# dm646x_cslr_pci_003 register map
Vendor: Texas Instruments
Peripheral module from a debugger description file.
Registers are 32-bit, access not given, reset 0x0 unless marked. A register's access mark holds for its fields unless they carry their own. Offsets are as the file gives them; lines under a group give offsets from that group; [hi:lo] are bit positions; {n}, {i} and the like mark numbered series; 'fields as' and 'values as' point back to an identical list; <NAME> marks a mode.

## PCI — The PCI module allows communication with devices complaint to the PCI Local Bus Specification (revision 2.3) via a 32-bit address/data bus operating at speeds up to 33 MHz.
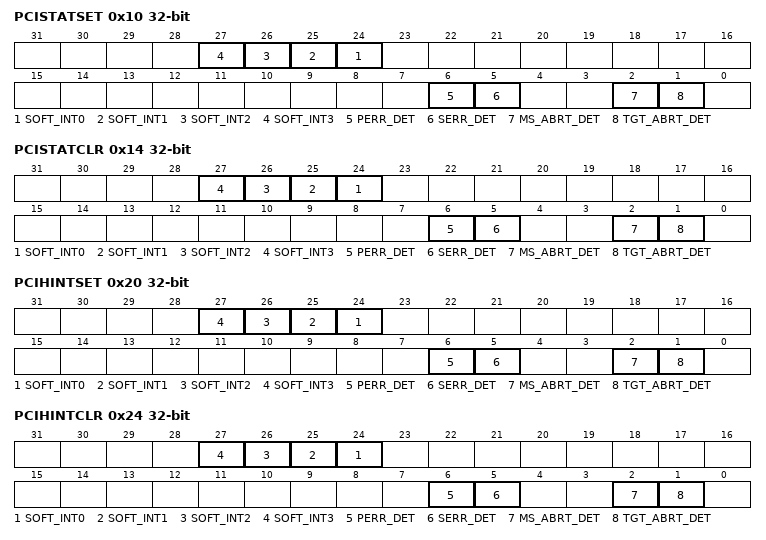
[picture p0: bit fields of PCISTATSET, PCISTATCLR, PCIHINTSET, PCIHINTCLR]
0x10 PCISTATSET — Used to set bits in the internal status register and to read the status of the internal status register.
  [all] fields
    0=NOTSET (Status bit is not set.); 1=SET (Status bit is set.)
  [n+24] SOFT_INT{n} rw (n=0..3) — Software interrupt status bit. Reading these bits returns the value of the SOFT_INT{n} bit in the internal status register. Writing a 1 to these bits sets the SOFT_INT{n} bit in the internal status register. Writing a 0 has no effect.
  [6] PERR_DET rw — Parity error detect status bit. Reading this bit returns the value of the PERR_DET bit in the internal status register. Writing 1 to this bit sets the PERR_DET bit in the internal status register.
  [5] SERR_DET rw — System error detect status bit. Reading this bit returns the value of the SERR_DET bit in the internal status register. Writing 1 to this bit sets the SERR_DET bit in the internal status register.
  [2] MS_ABRT_DET rw — Master abort detect status bit. Reading this bit returns the value of the MS_ABRT_DET bit in the internal status register. Writing 1 to this bit sets the MS_ABRT_DET bit in the internal status register.
  [1] TGT_ABRT_DET rw — Target abort detect status bit. Reading this bit returns the value of the TGT_ABRT_DET bit in the internal status register. Writing 1 to this bit sets the TGT_ABRT_DET bit in the internal status register.
0x14 PCISTATCLR — Used to clear bits in the internal status register and to read the status of the internal status register.
  [all] fields
    values as the fields of PCISTATSET
  [n+24] SOFT_INT{n} rw (n=0..3) — Software interrupt status bit. Reading these bits returns the value of the SOFT_INT{n} bit in the internal status register. Writing a 1 to these bits clears the SOFT_INT{n} bit in the internal status register. Writing a 0 has no effect.
  [6] PERR_DET rw — Parity error detect status bit. Reading this bit returns the value of the PERR_DET bit in the internal status register. Writing 1 to this bit clears the PERR_DET bit in the internal status register.
  [5] SERR_DET rw — System error detect status bit. Reading this bit returns the value of the SERR_DET bit in the internal status register. Writing 1 to this bit clears the SERR_DET bit in the internal status register.
  [2] MS_ABRT_DET rw — Master abort detect status bit. Reading this bit returns the value of the MS_ABRT_DET bit in the internal status register. Writing 1 to this bit clears the MS_ABRT_DET bit in the internal status register.
  [1] TGT_ABRT_DET rw — Target abort detect status bit. Reading this bit returns the value of the TGT_ABRT_DET bit in the internal status register. Writing 1 to this bit clears the TGT_ABRT_DET bit in the internal status register.
0x20 PCIHINTSET — Writing to PCIHINTSET sets bits in the internal host interrupt enable register. Reading from PCIHINTSET returns the status of the internal host interrupt enable register.
  [all] fields
    0=NOTSET (Enable bit is not set.); 1=SET (Enable bit is set.)
  [n+24] SOFT_INT{n} rw (n=0..3) — Software interrupt status bit. Reading this bit returns the value of the SOFT_INT{n} bit in the internal host interrupt enable register. Writing a 1 to this bit sets the SOFT_INT{n} bit in the internal host interrupt enable register. Writing a 0 has no effect.
  [6] PERR_DET rw — Software interrupt status bit. Reading this bit returns the value of the PERR_DET bit in the internal host interrupt enable register. Writing a 1 to this bit sets the PERR_DET bit in the internal host interrupt enable register. Writing a 0 has no effect.
  [5] SERR_DET rw — Software interrupt status bit. Reading this bit returns the value of the SERR_DET bit in the internal host interrupt enable register. Writing a 1 to these bits sets the SERR_DET bit in the internal host interrupt enable register. Writing a 0 has no effect.
  [2] MS_ABRT_DET rw — Software interrupt status bit. Reading this bit returns the value of the MS_ABRT_DET bit in the internal host interrupt enable register. Writing a 1 to this bit sets the MS_ABRT_DET bit in the internal host interrupt enable register. Writing a 0 has no effect.
  [1] TGT_ABRT_DET rw — Software interrupt status bit. Reading this bit returns the value of the TGT_ABRT_DET bit in the internal host interrupt enable register. Writing a 1 to this bit sets the TGT_ABRT_DET bit in the internal host interrupt enable register. Writing a 0 has no effect.
0x24 PCIHINTCLR — Writing to PCIHINTCLR clears bits in the internal host interrupt enable register. Reading from PCIHINTCLR returns the masked host status that is the bitwise ANDing of the internal status register and the internal host interrupt enable register.
  [all] fields
    values as the fields of PCIHINTSET
  [n+24] SOFT_INT{n} rw (n=0..3) — Software interrupt status bit. Reading this bit returns the value of the SOFT_INT{n} bit in the internal host interrupt enable register ANDed with the SOFT_INT{n} bit in the internal status register. Writing a 1 to this bit clears the SOFT_INT{n} bit in the internal host interrupt enable register. Writing a 0 has no effect.
  [6] PERR_DET rw — Software interrupt status bit. Reading this bit returns the value of the PERR_DET bit in the internal host interrupt enable register ANDed with the PERR_DET bit in the internal status register. Writing a 1 to this bit clears the PERR_DET bit in the internal host interrupt enable register. Writing a 0 has no effect.
  [5] SERR_DET rw — Software interrupt status bit. Reading this bit returns the value of the SERR_DET bit in the internal host interrupt enable register ANDed with the SERR_DET bit in the internal status register. Writing a 1 to this bit clears the SERR_DET bit in the internal host interrupt enable register. Writing a 0 has no effect.
  [2] MS_ABRT_DET rw — Software interrupt status bit. Reading this bit returns the value of the MS_ABRT_DET bit in the internal host interrupt enable register ANDed with the MS_ABRT_DET bit in the internal status register. Writing a 1 to this bit clears the MS_ABRT_DET bit in the internal host interrupt enable register. Writing a 0 has no effect.
  [1] TGT_ABRT_DET rw — Software interrupt status bit. Reading this bit returns the value of the TGT_ABRT_DET bit in the internal host interrupt enable register ANDed with the TGT_ABRT_DET bit in the internal status register. Writing a 1 to this bit clears the TGT_ABRT_DET bit in the internal host interrupt enable register. Writing a 0 has no effect.
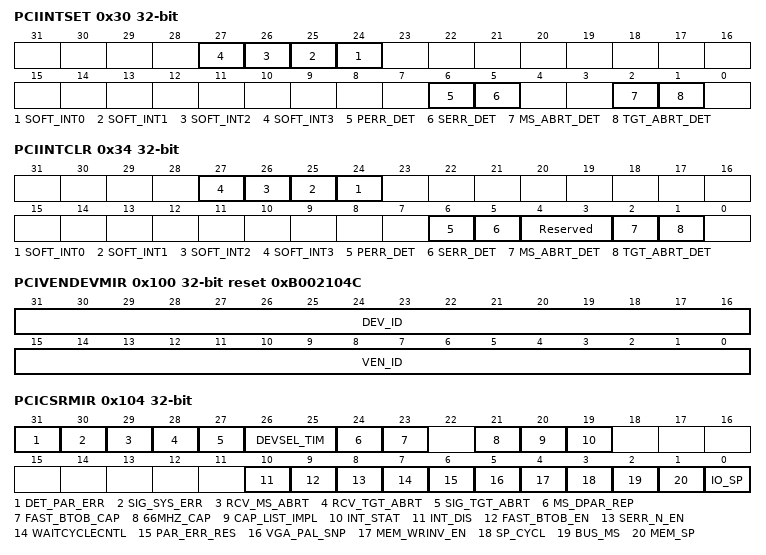
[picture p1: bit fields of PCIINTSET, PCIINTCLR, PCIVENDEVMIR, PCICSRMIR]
0x30 PCIINTSET — Writing to PCIINTSET sets bits in the internal CPU interrupt enable register. Reading from PCIINTSET returns the status of the internal interrupt enable register.
  [all] fields
    values as the fields of PCIHINTSET
  [n+24] SOFT_INT{n} rw (n=0..3) — Software interrupt status bit. Reading this bit returns the value of the SOFT_INT{n} bit in the internal CPU interrupt enable register. Writing a 1 to this bit sets the SOFT_INT{n} bit in the internal CPU interrupt enable register. Writing a 0 has no effect.
  [6] PERR_DET rw — Software interrupt status bit. Reading this bit returns the value of the PERR_DET bit in the internal CPU interrupt enable register. Writing a 1 to this bit sets the PERR_DET bit in the internal CPU interrupt enable register. Writing a 0 has no effect.
  [5] SERR_DET rw — Software interrupt status bit. Reading this bit returns the value of the SERR_DET bit in the internal CPU interrupt enable register. Writing a 1 to these bits sets the SERR_DET bit in the internal CPU interrupt enable register. Writing a 0 has no effect.
  [2] MS_ABRT_DET rw — Software interrupt status bit. Reading this bit returns the value of the MS_ABRT_DET bit in the internal CPU interrupt enable register. Writing a 1 to this bit sets the MS_ABRT_DET bit in the internal CPU interrupt enable register. Writing a 0 has no effect.
  [1] TGT_ABRT_DET rw — Software interrupt status bit. Reading this bit returns the value of the TGT_ABRT_DET bit in the internal CPU interrupt enable register. Writing a 1 to this bit sets the TGT_ABRT_DET bit in the internal CPU interrupt enable register. Writing a 0 has no effect.
0x34 PCIINTCLR — Writing to PCIINTCLR clears bits in the internal CPU interrupt enable register. Reading from PCIDINTCLR returns the masked CPU status that is the bitwise ANDing of the internal status register and the internal CPU interrupt enable register.
  [n+24] SOFT_INT{n} rw (n=0..3) — Software interrupt status bit. Reading this bit returns the value of the SOFT_INT{n} bit in the internal CPU interrupt enable register ANDed with the SOFT_INT{n} bit in the internal status register. Writing a 1 to this bit clears the SOFT_INT{n} bit in the internal CPU interrupt enable register. Writing a 0 has no effect.
    values as the fields of PCIHINTSET
  [6] PERR_DET rw — Software interrupt status bit. Reading this bit returns the value of the PERR_DET bit in the internal CPU interrupt enable register ANDed with the PERR_DET bit in the internal status register. Writing a 1 to this bit clears the PERR_DET bit in the internal CPU interrupt enable register. Writing a 0 has no effect.
    values as the fields of PCIHINTSET
  [5] SERR_DET rw — Software interrupt status bit. Reading this bit returns the value of the SERR_DET bit in the internal CPU interrupt enable register ANDed with the SERR_DET bit in the internal status register. Writing a 1 to this bit clears the SERR_DET bit in the internal CPU interrupt enable register. Writing a 0 has no effect.
    values as the fields of PCIHINTSET
  [4:3] Reserved — (access N)
  [2] MS_ABRT_DET rw — Software interrupt status bit. Reading this bit returns the value of the MS_ABRT_DET bit in the internal CPU interrupt enable register ANDed with the MS_ABRT_DET bit in the internal status register. Writing a 1 to this bit clears the MS_ABRT_DET bit in the internal CPU interrupt enable register. Writing a 0 has no effect.
    values as the fields of PCIHINTSET
  [1] TGT_ABRT_DET rw — Software interrupt status bit. Reading this bit returns the value of the TGT_ABRT_DET bit in the internal CPU interrupt enable register ANDed with the TGT_ABRT_DET bit in the internal status register. Writing a 1 to this bit clears the TGT_ABRT_DET bit in the internal CPU interrupt enable register. Writing a 0 has no effect.
    values as the fields of PCIHINTSET
0x100 PCIVENDEVMIR rw reset 0xB002104C — This register is used to initialize the Vendor ID and / or Device ID in the PCI Configuration Space.
  [31:16] DEV_ID — Device ID bits. Identifies a specific device from the manufacturer.
  [15:0] VEN_ID — Vendor ID bits. Uniquely identifies the manufacturer of the device.
0x104 PCICSRMIR (reset mask 0xF9FFFFFF) — This register is used to initialize certain bits in the PCI Configuration Space Command / Status register.
  [31] DET_PAR_ERR rw — Detected parity error bit. This bit is set by the PCI to indicate that it detected a parity error, which was not necessarily reported on PPERRz if parity reporting is disabled.
    0=CLEARED (No error has been detected.); 1=SET (Error has been detected.)
  [30] SIG_SYS_ERR rw — Signaled system error (PSERRz) bit. This bit is set by the PCI to indicate that it signaled a system error on the PSERRz pin.
    values as DET_PAR_ERR
  [29] RCV_MS_ABRT rw — Received master abort bit. This bit is set by the PCI master unit in the PCI to indicate that it terminated a transaction with a master abort.
    0=CLEARED (No error has been detected.); 1=SET (Received master abort.)
  [28] RCV_TGT_ABRT rw — Received target abort bit. This bit is set by the PCI master unit in the PCI to indicate that it has received a target abort when acting as a bus master.
    0=CLEARED (No error has been detected.); 1=SET (Received target abort.)
  [27] SIG_TGT_ABRT ro — Signaled target abort bit. This bit is always 0 because the PCI cannot issue a target abort.
  [26:25] DEVSEL_TIM ro — Device select (PDEVSELz) timing bits. These bits indicate the decode response time capability of the device. The PCI decode logic supports medium PDEVSELz timing; therefore, these bits are hardwired to 01.
  [24] MS_DPAR_REP rw — Master data parity error bit. This bit is set by the PCI when all of the following conditions are met: 1. The PCI asserted PPERRz or observed PPERRz asserted. 2. The PCI was the bus master during the observed PPERRz assertion. 3. The parity error response bit (PAR_ERR_RES) is set.
    0=CLEARED (No error has been detected.); 1=SET (Reported master data parity error.)
  [23] FAST_BTOB_CAP ro — Fast back-to-back capable bit. This bit indicates that the device is capable of performing fast back-to-back transactions. The PCI does not support fast back-to-back transactions; therefore, this bit is hardwired to 0.
  [21] 66MHZ_CAP rw — 66MHz capable bit. This bit indicates whether or not the interface is capable of meeting the 66MHz PCI timing requirements.
  [20] CAP_LIST_IMPL rw — Capabilities list implemented bit. This bit indicates whether or not the interface provides at least one capabilities list.
  [19] INT_STAT ro — Interrupt status bit. This bit indicates the current interrupt status for the function as generated by the interrupt registers in the back end interface. If this bit is set and INT_DIS is cleared, the PINTAz pin will be asserted low. INT_DIS has no effect on the value of this bit.
    0=CLEARED (Interrupt is not set.); 1=SET (Interrupt is set.)
  [10] INT_DIS rw — PINTAz disable bit. This bit controls whether or not the device can assert the PINTAz pin. This bit is a disable for the output driver on the PINTAz pin. If this bit is set, the interrupt condition will not appear on the external PINTAz pin.
    0=CLEARED (Device cannot assert PINTAz pin.); 1=SET (Device can assert PINTAz pin.)
  [9] FAST_BTOB_EN ro — Fast back-to-back enable bit. This bit controls whether or not the device is allowed to perform back-to-back writes to different targets. The PCI will not perform fast back-to-back transactions; therefore, this bit is hardwired to a 0.
  [8] SERR_N_EN rw — PSERRz enable bit. This bit is an enable for the output driver on the PSERRz pin. If this bit is cleared, and a system error condition is set inside the PCI, the error signal will not appear on the SERRz pin.
    0=CLEARED (Device cannot assert SERRz pin.); 1=SET (Device can assert SERRz pin.)
  [7] WAITCYCLECNTL ro — Waite cycle control bit. This bit indicates whether or not the device performs address stepping. The PCI does not support address stepping; therefore this bit is hardwired to 0.
  [6] PAR_ERR_RES rw — Parity error response bit. This bit controls whether or not the device responds to detected parity errors. If this bit is set, the PCI will respond normally to parity errors. If this bit is cleared, the PCI will set its Detected Parity Error bit (DET_PAR_ERR) when an error is detected, but does not assert PPERRz and continues normal operation.
    0=CLEARED (Device will set the DET_PAR_ERR bit, but it will not assert the PPERRz pin.); 1=SET (Device will respond normally to parity errors.)
  [5] VGA_PAL_SNP ro — VGA Palette Snoop bit. This bit is not applicable for the PCI and is hardwired to a 0.
  [4] MEM_WRINV_EN rw — Memory write and invalidate enable bit. This bit enables the device to use the Memory Write and Invalidate command. If this bit is cleared, the PCI will not attempt to use the Memory Write and Invalidate command.
    0=CLEARED (PCI will not use Memory Write and Invalidate commands.); 1=SET (PCI will can use Memory Write and Invalidate commands.)
  [3] SP_CYCL rw — Special cycle bit. This bit controls the device's response to special cycle commands. If this bit is cleared, the device will ignore all special cycle commands. If this bit is set to 1, the device can monitor special cycle commands.
    0=CLEARED (Device will ingore special cycle commands.); 1=SET (Device will monitor special cycle commands.)
  [2] BUS_MS rw — Bus master bit. This bit enables the device to act as a PCI bus master. If this bit is cleared, the device will not act as a master on the PCI bus.
    0=CLEARED (Device cannot act as a bus master.); 1=SET (Device can act as a bus master.)
  [1] MEM_SP rw — Memory access bit. This bit enables the device to respond to memory accesses within its address space. If this bit is cleared, the PCI will not respond to memory mapped accesses.
    0=CLEARED (Device will not respond to memory accesses.); 1=SET (Device will respond to memory accesses.)
  [0] IO_SP ro — IO access bit. This bit enables the device to respond to I/O accesses within its address space. The PCI does not support IO accesses as a slave; therefore, this bit is hardwired to 0.
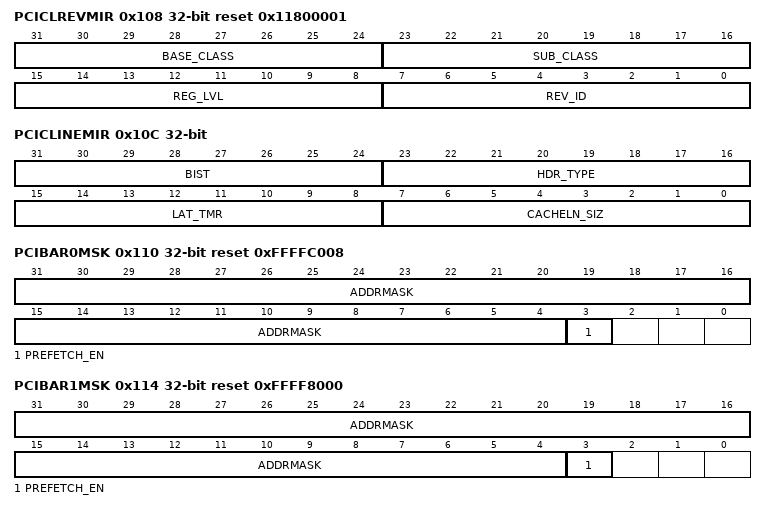
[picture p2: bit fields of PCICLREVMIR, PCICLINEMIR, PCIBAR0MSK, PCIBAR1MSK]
0x108 PCICLREVMIR rw reset 0x11800001 — This register is used to initialize the Class Code and / or Revision ID
  [31:24] BASE_CLASS — Base class bits.
  [23:16] SUB_CLASS — Sub-class bits.
  [15:8] REG_LVL — Register-level programming interface bits.
  [7:0] REV_ID — Revision ID bits. Identifies a revision of the specific device.
0x10C PCICLINEMIR access per field — This register is used to set latency timer and cacheline size
  [31:24] BIST ro — Built-in Self Test bit. Hardwired to 0
  [23:16] HDR_TYPE ro — Header Type identifies the layout of bytes 10h through 3Fh and if the device is single or multi-function
  [15:8] LAT_TMR rw — Latency timer bits. The latency timer register is provided so that the host can restrict the continued usage of the PCI bus by a master involved in a multiple data cycle transaction after its PGNTz has been removed. The host is required to write a value into this register indicating the maximum number of PCI cycles for which the master can hold the bus (beginning from the assertion of PFRAMEz). If PGNTz is never removed during the transaction, the value in the latency timer value will not be used. Since the PCI will support transactions with multiple data cycles, the latency timer register is implemented. The latency timer register is initialized with all zeroes at reset. This register is not cleared on software reset.
  [7:0] CACHELN_SIZ rw — Cache line size bits. This register is provided so that the host can inform the device of the cache line size in units of 32 bit words. The value of this register is used by the PCI as a master device to determine whether to use Memory Write, Memory Write and Invalidate, Read, Read Line, or Read Multiple commands for accessing memory. This register is also used by the slave state machine to determine the size of prefetches that are performed on the Slave Back End Interface. Supported values for this register are as listed. Writing an unsupported value to this register will result in the value cleared to 0, as specified in the PCI Local Bus Specification.
    0=DIS (Disabled.); 4=16BYTES (Cache Line is 16 bytes); 8=32BYTES (Cache Line is 32 bytes); 22=64BYTES (Cache Line is 64 bytes); 50=128BYTES (Cache Line is 128 bytes)
0x110 PCIBAR0MSK reset 0xFFFFC008 — The Base Address Mask Register 0 controls the size and prefetchability of the PCI Configuration Base Address Register 0
  [31:4] ADDRMASK rw — Address mask bits. These bits control the writeability of the corresponding bits in the base address 0 mirror register (PCIBAR0MIR).
  [3] PREFETCH_EN rw — Prefetchable enable bit. Specifies whether or not the slave memory window controlled by the base address 0 mirror register (PCIBAR0MIR) is prefetchable. This bit is reflected in the PREFETCH bit in PCIBAR0MIR.
    0=NONPREFETCH (Memory space is not prefetchable.); 1=PREFETCH (Memory space is prefetchable.)
0x114 PCIBAR1MSK reset 0xFFFF8000 — The Base Address Mask Register 1 controls the size and prefetchability of the PCI Configuration Base Address Register 1
  [31:4] ADDRMASK rw — Address mask bits. These bits control the writeability of the corresponding bits in the base address 1mirror register (PCIBAR1MIR).
  [3] PREFETCH_EN rw — Prefetchable enable bit. Specifies whether or not the slave memory window controlled by the base address 1 mirror register (PCIBAR1MIR) is prefetchable. This bit is reflected in the PREFETCH bit in PCIBAR1MIR.
    values as PCIBAR0MSK.PREFETCH_EN
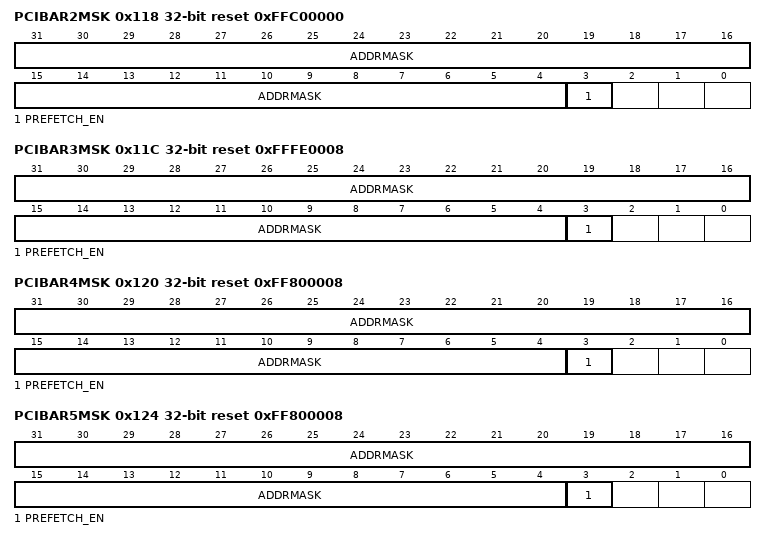
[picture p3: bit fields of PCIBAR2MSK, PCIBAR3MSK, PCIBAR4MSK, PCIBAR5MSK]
0x118 PCIBAR2MSK reset 0xFFC00000 — The Base Address Mask Register 2 controls the size and prefetchability of the PCI Configuration Base Address Register 2
  [31:4] ADDRMASK rw — Address mask bits. These bits control the writeability of the corresponding bits in the base address 2 mirror register (PCIBAR2MIR).
  [3] PREFETCH_EN rw — Prefetchable enable bit. Specifies whether or not the slave memory window controlled by the base address 2 mirror register (PCIBAR2MIR) is prefetchable. This bit is reflected in the PREFETCH bit in PCIBAR2MIR.
    values as PCIBAR0MSK.PREFETCH_EN
0x11C PCIBAR3MSK reset 0xFFFE0008 — The Base Address Mask Register 3 controls the size and prefetchability of the PCI Configuration Base Address Register 3
  [31:4] ADDRMASK rw — Address mask bits. These bits control the writeability of the corresponding bits in the base address 3 mirror register (PCIBAR3MIR).
  [3] PREFETCH_EN rw — Prefetchable enable bit. Specifies whether or not the slave memory window controlled by the base address 3 mirror register (PCIBAR3MIR) is prefetchable. This bit is reflected in the PREFETCH bit in PCIBAR3MIR.
    values as PCIBAR0MSK.PREFETCH_EN
0x120 PCIBAR4MSK reset 0xFF800008 — The Base Address Mask Register 4 controls the size and prefetchability of the PCI Configuration Base Address Register 4
  [31:4] ADDRMASK rw — Address mask bits. These bits control the writeability of the corresponding bits in the base address 4 mirror register (PCIBAR4MIR).
  [3] PREFETCH_EN rw — Prefetchable enable bit. Specifies whether or not the slave memory window controlled by the base address 4 mirror register (PCIBAR4MIR) is prefetchable. This bit is reflected in the PREFETCH bit in PCIBAR4MIR.
    values as PCIBAR0MSK.PREFETCH_EN
0x124 PCIBAR5MSK reset 0xFF800008 — The Base Address Mask Register 5 controls the size and prefetchability of the PCI Configuration Base Address Register 5
  [31:4] ADDRMASK rw — Address mask bits. These bits control the writeability of the corresponding bits in the base address 5 mirror register (PCIBAR5MIR).
  [3] PREFETCH_EN rw — Prefetchable enable bit. Specifies whether or not the slave memory window controlled by the base address 5 mirror register (PCIBAR5MIR) is prefetchable. This bit is reflected in the PREFETCH bit in PCIBAR5MIR.
    values as PCIBAR0MSK.PREFETCH_EN
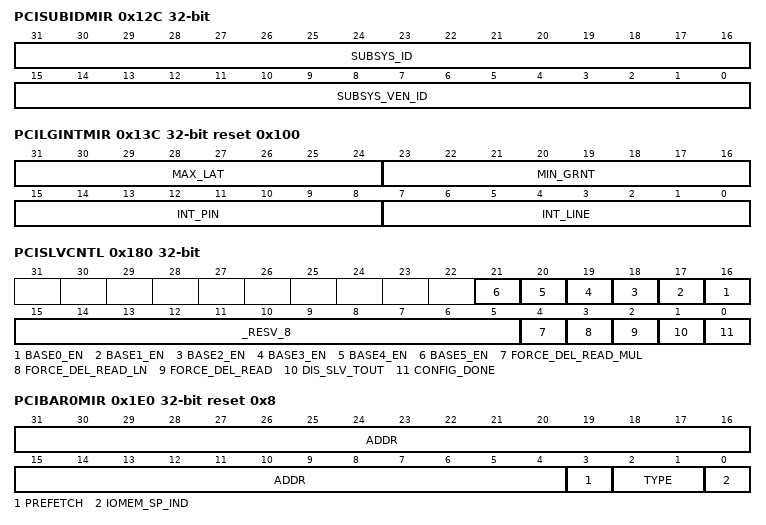
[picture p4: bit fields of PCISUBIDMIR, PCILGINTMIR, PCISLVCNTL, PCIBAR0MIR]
0x12C PCISUBIDMIR rw — PCI Subsystem Vendor ID / Subsystem ID
  [31:16] SUBSYS_ID — Subsystem ID bits. Identifies the board level device. The Subsystem ID is specified by the board level manufacturer.
  [15:0] SUBSYS_VEN_ID — Subsystem Vendor ID bits. Identifies the board level manufacturer. The Subsystem Vendor ID is specified by the PCI Special Interest Group.
0x134 PCICPBPTRMIR reset 0x40 — Capabilities Pointer
  [7:0] CAP ro — Capabilities pointer bits. Specifies the address in configuration space where the first entry in the capabilities list is located.
0x13C PCILGINTMIR access per field reset 0x100 — Set Max Latency / Min Grant
  [31:24] MAX_LAT rw — Maximum latency bits. Specifies how often the device needs to gain access to the PCI bus in 0.25 msec units.
  [23:16] MIN_GRNT rw — Minimum grant bits. Specifies the length of the burst period for the device in 0.25 msec units.
  [15:8] INT_PIN ro — Interrupt pin bits. Specifies the interrupt pin the device uses. This bit is hardwired to 01h in the PCI to indicate that interrupt A (PINTAz) will be used.
  [7:0] INT_LINE rw — Interrupt line bits. This value is written by the host and indicates to which input of the system interrupt controller the PCI interrupt pin is connected.
0x180 PCISLVCNTL (reset mask 0xFFC0FFFF) — PCI Slave Control
  [n+16] BASE{n}_EN rw (n=0..5) — Base address {n} enable bit. This bit enables/disables the base address {n} register. When BASE{n}_EN is cleared to 0 (disabled) any host accesses targeted at the slave memory window covered by the base address register is ignored. Host writes to the base address registers are not affected by BASE{n}_EN.
    0=DISABLE (Disable base address {n} register.); 1=ENABLE (Enable base address {n} register.)
  [15:5] _RESV_8 — (access N)
  [4] FORCE_DEL_READ_MUL rw — Force Delayed Read Multiple bit.
    0=NORMAL (Slave should respond with normal 16 clock cycle timeout and retry mechanism for Memory Read Multiple transactions); 1=IMMEDIATE (Slave should immediately respond with a retry whenever a Memory Read Multiple transaction is decoded for this slave. This bit overrides the DIS_SLV_TOUT bit for Memory Read Multiple transactions.)
  [3] FORCE_DEL_READ_LN rw — Force Delayed Read Line bit.
    0=NORMAL (Slave should respond with normal 16 clock cycle timeout and retry mechanism for memory Read Line transactions); 1=IMMEDIATE (Slave should immediately respond with a retry whenever a Memory Read Line transaction is decoded for this slave. This bit overrides the DIS_SLV_TOUT bit for Memory Read Line transactions.)
  [2] FORCE_DEL_READ rw — Force Delayed Read bit.
    0=NORMAL (Slave should respond with normal 16 clock cycle timeout and retry mechanism for memory Read transactions); 1=IMMEDIATE (Slave should immediately respond with a retry whenever a Memory Read transaction is decoded for this slave. This bit overrides DIS_SLV_TOUT for Memory Read transactions.)
  [1] DIS_SLV_TOUT rw — Disable Slave timeout bit.
    0=NORMAL (Slave responds with normal 16 clock cycle timeout mechanism); 1=WAITSTATES (Slave will insert wait states on the PCI bus indefinitely until the access is ready to complete)
  [0] CONFIG_DONE rw — Configuration done bit. Indicates if the configuration registers have been loaded with their proper reset values. Although this bit defaults to 0, the on-chip ROM Boot Loader will set this bit to 1.
    0=CLEAR (Configuration registers are being loaded. No access allowed into PCI interface.); 1=SET (Configuration registers loading is complete. PCI interface will accept accesses.)
0x1C0 PCIBAR0TRL reset 0x10000000 — The slave base address translation registers control the translation of transaction addresses as they flow from the PCI bus to the internal CPU.
  [31:4] TRANS_ADDR rw — Translation address bits. These address bits replace the address bits of a PCI slave transaction. The ADDRMASK bits of the base address n mask registers (PCIBAR0MSK) specify which bits are replaced in the original PCI address.
0x1C4 PCIBAR1TRL reset 0x20000000 — This register control the translation of transaction addresses
  [31:4] TRANS_ADDR rw — Translation address bits. These address bits replace the address bits of a PCI slave transaction. The ADDRMASK bits of the base address n mask registers (PCIBAR1MSK) specify which bits are replaced in the original PCI address.
0x1C8 PCIBAR2TRL reset 0x1C00000 — This register control the translation of transaction addresses
  [31:4] TRANS_ADDR rw — Translation address bits. These address bits replace the address bits of a PCI slave transaction. The ADDRMASK bits of the base address n mask registers (PCIBAR2MSK) specify which bits are replaced in the original PCI address.
0x1CC PCIBAR3TRL reset 0x11818000 — This register control the translation of transaction addresses
  [31:4] TRANS_ADDR rw — Translation address bits. These address bits replace the address bits of a PCI slave transaction. The ADDRMASK bits of the base address n mask registers (PCIBAR3MSK) specify which bits are replaced in the original PCI address.
0x1D0 PCIBAR4TRL reset 0x80000000 — This register control the translation of transaction addresses
  [31:4] TRANS_ADDR rw — Translation address bits. These address bits replace the address bits of a PCI slave transaction. The ADDRMASK bits of the base address n mask registers (PCIBAR4MSK) specify which bits are replaced in the original PCI address.
0x1D4 PCIBAR5TRL reset 0x80800000 — This register control the translation of transaction addresses
  [31:4] TRANS_ADDR rw — Translation address bits. These address bits replace the address bits of a PCI slave transaction. The ADDRMASK bits of the base address n mask registers (PCIBAR5MSK) specify which bits are replaced in the original PCI address.
0x1E0 PCIBAR0MIR access per field reset 0x8 — PCI Base Address 0 Mirror Register
  [31:4] ADDR rw — Address bits. These bits can be written by the host to allow initialization of the base address at startup. The writeability of individual bits is determined by the corresponding bit in the base address n mask register (PCIBARnMSK).
  [3] PREFETCH ro — Prefetchable bit. Specifies whether or not the memory space controlled by this base address register is prefetchable. This bit reflects the value that is input from the PREFETCH_EN bit in the base address n mask register (PCIBARnMSK).
    values as PCIBAR0MSK.PREFETCH_EN
  [2:1] TYPE ro — Type bits. Indicates the size of the base address register/decoder. This version of the PCI only supports 32-bit addressing, so these bits are hardwired to 0.
  [0] IOMEM_SP_IND ro — IO/Memory Space Indicator bit. Indicates whether the base address maps into the host's memory or I/O space. This version of the PCI only supports memory-mapped base address registers, so this bit is hardwired to 0.
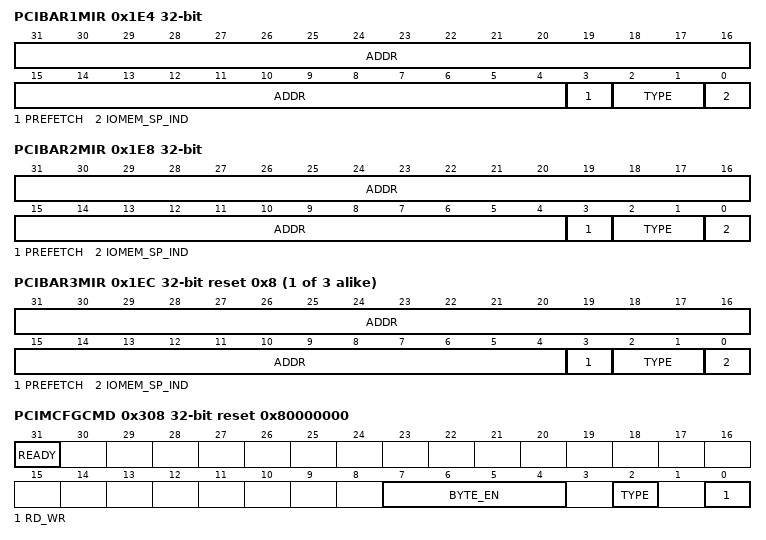
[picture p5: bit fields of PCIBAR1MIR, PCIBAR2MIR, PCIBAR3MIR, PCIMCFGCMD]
0x1E4 PCIBAR1MIR access per field — PCI Base Address 1 Mirror Register
  fields as PCIBAR0MIR
0x1E8 PCIBAR2MIR access per field — PCI Base Address 2 Mirror Register
  fields as PCIBAR0MIR
{0x1E0+4i} PCIBAR{i}MIR access per field reset 0x8 (i=3..5) — PCI Base Address {i} Mirror Register
  fields as PCIBAR0MIR
0x300 PCIMCFGDAT rw — PCI Master Configuration / IO Access Data Register
  [31:0] DATA — Data bits. Software writes the data into this register for a configuration/IO write or reads the data from this register for a configuration/IO read.
0x304 PCIMCFGADR rw — PCI Master Configuration / IO Access Address Register
  [31:0] ADDR — Address bits. The address bits provide the address for configuration/IO transactions. Bits 1-0 are ignored for a configuration transaction. Software must ensure that bits 1-0 of the address correspond to the BYTE_EN bits in the master configuration/IO access command register (PCIMCFGCMD) for IO transactions, thus ensuring that the access is valid on the PCI bus.
0x308 PCIMCFGCMD reset 0x80000000 — PCI Master Configuration / IO Access Command Register
  [31] READY ro — Ready bit.This bit should be checked to assure that previous transaction is completed.
    0=NOTREADY (Register is not ready to accept a new command)
  [7:4] BYTE_EN rw — Byte Enables. This bit used to determine which bytes within the addressed DWORD are being accessed. Byte enables indicate the size of the transfer and must be consistent with the Bits 1:0 of the Address which is specified using the PCI Master Configuration/IO Access Address Register.
  [2] TYPE rw — Type bit. Select Configuration or IO Transaction.
    0=CONFIG_SPACE (Configuration transaction.); 1=IO_SPACE (IO transaction.)
  [0] RD_WR rw — Read/write bit.Select read or write operation.
    0=WRITE; 1=READ
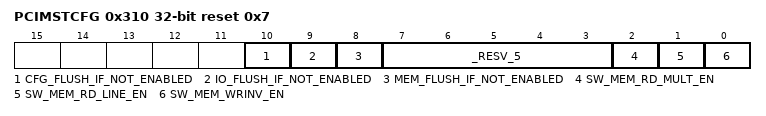
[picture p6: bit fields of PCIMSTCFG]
0x310 PCIMSTCFG reset 0x7 — PCI Master Configuration Register
  [10] CFG_FLUSH_IF_NOT_ENABLED rw — Configuration flush bit. Controls whether or not the PCI will flush configuration transactions from the proxy registers, if the PCI is not enabled as a master (BUS_MS = 0 in command/status register).
    0=NO_FLUSH (PCI does not flush configuration transactions from the proxy registers.); 1=FLUSH (PCI flushes configuration transactions from the proxy registers.)
  [9] IO_FLUSH_IF_NOT_ENABLED rw — IO flush bit. Controls whether or not the PCI will flush I/O transactions from the proxy registers, if the PCI is not enabled as a master (BUS_MS = 0 in command/status register).
    0=NO_FLUSH (PCI does not flush I/O transactions from the proxy registers.); 1=FLUSH (PCI flushes I/O transactions from the proxy registers.)
  [8] MEM_FLUSH_IF_NOT_ENABLED rw — Memory flush bit. Controls whether or not the PCI will flush master transactions from the PCI, if the PCI is not enabled as a master (BUS_MS = 0 in command/status register).
    0=NO_FLUSH (PCI does not flush transactions on the PCIM interface.); 1=FLUSH (1 PCI flushes transactions on the PCIM interface.)
  [7:3] _RESV_5 — (access N)
  [2] SW_MEM_RD_MULT_EN rw — Memory read multiple enable bit. Controls whether or not the PCI command generation logic is permitted to use the Memory Read Multiple command.
    0=DISABLE_MRM (PCI will not generate Memory Read Multiple transactions.); 1=ENABLE_MRM (PCI is enabled to generate Memory Read Multiple transactions for appropriate length bursts.)
  [1] SW_MEM_RD_LINE_EN rw — Memory read line enable bit. Controls whether or not the PCI command generation logic is permitted to use the Memory Read Line command.
    0=DISABLE_MRL (PCI will not generate Memory Read Line transactions.); 1=ENABLE_MRL (PCI is enabled to generate Memory Read Line transactions for appropriate length bursts.)
  [0] SW_MEM_WRINV_EN rw — Memory write invalid enable bit. Controls whether or not the PCI command generation logic is permitted to use the Memory Write and Invalidate command.
    0=DISABLE_MWI (PCI will not generate Memory Write and Invalidate transactions.); 1=ENABLE_MWI (PCI is enabled to generate Memory Write and Invalidate transactions for appropriate length bursts.)
0x314 PCIADDSUB[32] — The DM646x DMSoc-to-PCI Address Translation registers are used for address translation from the device to PCI domain
  [31:23] ADD_SUBS rw — Address substitution bits. Substitutes the 9 MSBs of the DM646x DMSoC address during Device-to-PCI transactions.
0x394 PCIVENDEVPRG rw reset 0xB002104C — PCI Vendor ID and Device ID Program Register
  [31:0] VENDOR_DEVICE_ID_PROG — This bit provides the default values for VEN_ID and DEV_ID
0x39C PCICLREVPRG rw reset 0x11800001 — Provides default values to Class code/Revision ID mirror register
  [31:0] CLASS_CODE_REV_ID_PROG — This bit provides default values to CL_ CODE and REV_ID
0x3A0 PCISUBIDPRG rw — Provides default values to subsystem vendor id and subsystem id
  [31:0] SUBSYS_VENDOR_ID_SUBSYS_ID_PROG — This bit provides default value to SUBSYS_VEN_ID and SUBSYS_ID
0x3A4 PCIMAXLGPRG — Provides default values for max latency and min grant
  [15:0] MAX_LAT_MIN_GRANT_PROG rw — This bit Provides default values for MAX_LAT,MIN_GRNT
0x3AC PCICFGDONE — Supplies configuration done to PCI core
  [0] CONFIG_DONE rw — Configuration done bit. Holds off accesses by external hosts to the PCI until configuration by the on-chip ROM Boot Loader is complete.
    0=NOTDONE (Configuration in progress, accesses to the PCI are not permitted.); 1=DONE (Configuration complete, accesses to the PCI are allowed.)
